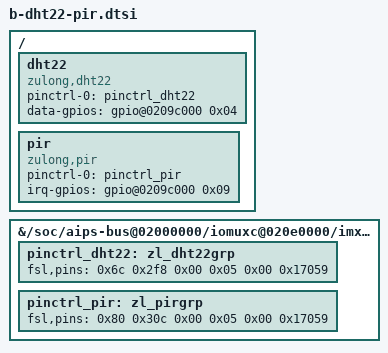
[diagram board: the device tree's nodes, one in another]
/* 追加到反编译的 board.dts 末尾：DHT22 + PIR 节点与 pinctrl */

&{/soc/aips-bus@02000000/iomuxc@020e0000/imx6ul-evk} {
	pinctrl_dht22: zl_dht22grp {
		fsl,pins = <0x6c 0x2f8 0x00 0x05 0x00 0x17059>;	/* MX6UL_PAD_GPIO1_IO04__GPIO1_IO04 */
	};

	pinctrl_pir: zl_pirgrp {
		fsl,pins = <0x80 0x30c 0x00 0x05 0x00 0x17059>;	/* MX6UL_PAD_GPIO1_IO09__GPIO1_IO09 */
	};
};

/ {
	dht22 {
		compatible = "zulong,dht22";
		pinctrl-names = "default";
		pinctrl-0 = <&pinctrl_dht22>;
		data-gpios = <&{/soc/aips-bus@02000000/gpio@0209c000} 0x04 0x00>;
		status = "okay";
	};

	pir {
		compatible = "zulong,pir";
		pinctrl-names = "default";
		pinctrl-0 = <&pinctrl_pir>;
		irq-gpios = <&{/soc/aips-bus@02000000/gpio@0209c000} 0x09 0x00>;
		status = "okay";
	};
};
